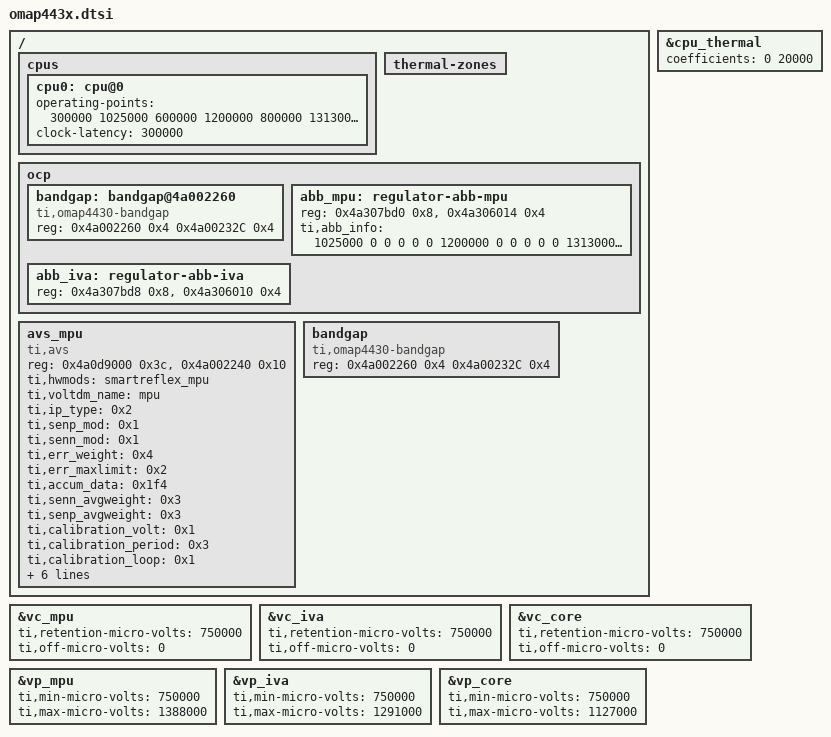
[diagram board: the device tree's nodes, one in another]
/*
 * Device Tree Source for OMAP443x SoC
 *
 * Copyright (C) 2013 Texas Instruments Incorporated - http://www.ti.com/
 *
 * This file is licensed under the terms of the GNU General Public License
 * version 2.  This program is licensed "as is" without any warranty of any
 * kind, whether express or implied.
 */

#include "omap4.dtsi"

/ {
	cpus {
		cpu0: cpu@0 {
			/* OMAP443x variants OPP50-OPPNT */
			operating-points = <
				/* kHz    uV */
				300000  1025000
				600000  1200000
				800000  1313000
				1008000 1375000
			>;
			clock-latency = <300000>; /* From legacy driver */

			/* cooling options */
			#cooling-cells = <2>; /* min followed by max */
		};
	};

	thermal-zones {
		#include "omap4-cpu-thermal.dtsi"
	};

	ocp {
		bandgap: bandgap@4a002260 {
			reg = <0x4a002260 0x4
			       0x4a00232C 0x4>;
			compatible = "ti,omap4430-bandgap";

			#thermal-sensor-cells = <0>;
		};
	};

	ocp {
		abb_mpu: regulator-abb-mpu {
			status = "okay";

			reg = <0x4a307bd0 0x8>, <0x4a306014 0x4>;
			reg-names = "base-address", "int-address";

			ti,abb_info = <
			/*uV		ABB	efuse	rbb_m	fbb_m	vset_m*/
			1025000		0	0	0	0	0
			1200000		0	0	0	0	0
			1313000		0	0	0	0	0
			1375000		1	0	0	0	0
			1389000		1	0	0	0	0
			>;
		};

		/* Default unused, just provide register info for record */
		abb_iva: regulator-abb-iva {
			reg = <0x4a307bd8 0x8>, <0x4a306010 0x4>;
			reg-names = "base-address", "int-address";
		};
        };

	avs_mpu {
		compatible = "ti,avs";
		reg = <0x4a0d9000 0x3c>, <0x4a002240 0x10>;
		reg-names = "base-address", "efuse-address";
		#address-cells = <1>;
		#size-cells = <1>;
		ti,hwmods = "smartreflex_mpu";
		ti,voltdm_name = "mpu";
		ti,ip_type = <0x2>;
		ti,senp_mod = <0x1>;
		ti,senn_mod = <0x1>;
		ti,err_weight = <0x4>;
		ti,err_maxlimit = <0x2>;
		ti,accum_data = <0x1f4>;
		ti,senn_avgweight = <0x3>;
		ti,senp_avgweight = <0x3>;
		ti,calibration_volt = <0x1>;
		ti,calibration_period = <0x3>;
		ti,calibration_loop = <0x1>;
		ti,fuse_len_24bits;
		ti,autocomp_active;
		ti,boot_voltage = <1200000>;
		ti,avs_info = <
		/* uV	efuse	errminlimit errgain	volt_margin*/
		1025000	0x0	0xf4		0x0c	0
		1200000	0x3	0xf9		0x16	0
		1313000	0x6	0xfa		0x23	0
		1375000	0x9	0xfa		0x27	0
		>;
		pmic-supply = <&omap_twl6030_vcore1>;
	};

	bandgap {
		reg = <0x4a002260 0x4
		       0x4a00232C 0x4>;
		compatible = "ti,omap4430-bandgap";
	};

};

&cpu_thermal {
	coefficients = <0 20000>;
};

/include/ "omap443x-clocks.dtsi"

&vc_mpu {
	ti,retention-micro-volts = <750000>;
	ti,off-micro-volts = <0>;
};

&vc_iva {
	ti,retention-micro-volts = <750000>;
	ti,off-micro-volts = <0>;
};

&vc_core {
	ti,retention-micro-volts = <750000>;
	ti,off-micro-volts = <0>;
};

&vp_mpu {
	ti,min-micro-volts = <750000>;
	ti,max-micro-volts = <1388000>;
};

&vp_iva {
	ti,min-micro-volts = <750000>;
	ti,max-micro-volts = <1291000>;
};

&vp_core {
	ti,min-micro-volts = <750000>;
	ti,max-micro-volts = <1127000>;
};
